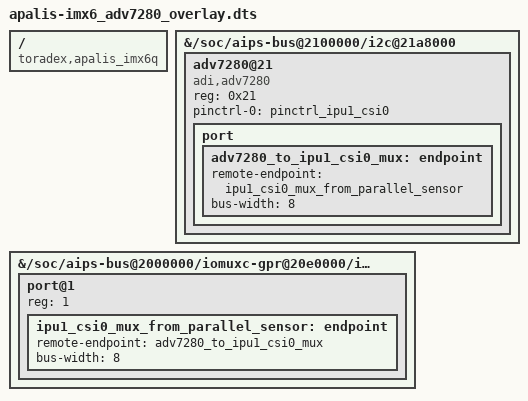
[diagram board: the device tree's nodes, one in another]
// Analogue Camera Adapter orderable at Toradex.

/dts-v1/;
/plugin/;

/ {
	compatible = "toradex,apalis_imx6q";

	fragment@0 {
		target-path = "/soc/aips-bus@2100000/i2c@21a8000";
		__overlay__ {
			#address-cells = <1>;
			#size-cells = <0>;
			status = "okay";

			adv7280@21 {
				compatible = "adi,adv7280";
				reg = <0x21>;
				pinctrl-names = "default";
				pinctrl-0 = <&pinctrl_ipu1_csi0>;

				port {
					adv7280_to_ipu1_csi0_mux: endpoint {
						remote-endpoint = <&ipu1_csi0_mux_from_parallel_sensor>;
						bus-width = <8>;
					};
				};
			};
		};
	};

	fragment@1 {
		target-path = "/soc/aips-bus@2000000/iomuxc-gpr@20e0000/ipu1_csi0_mux/";
		__overlay__ {
			#address-cells = <1>;
			#size-cells = <0>;
			status = "okay";

			port@1 {
				reg = <1>;

				ipu1_csi0_mux_from_parallel_sensor: endpoint {
					remote-endpoint = <&adv7280_to_ipu1_csi0_mux>;
					bus-width = <8>;
				};
			};
		};
	};
};
